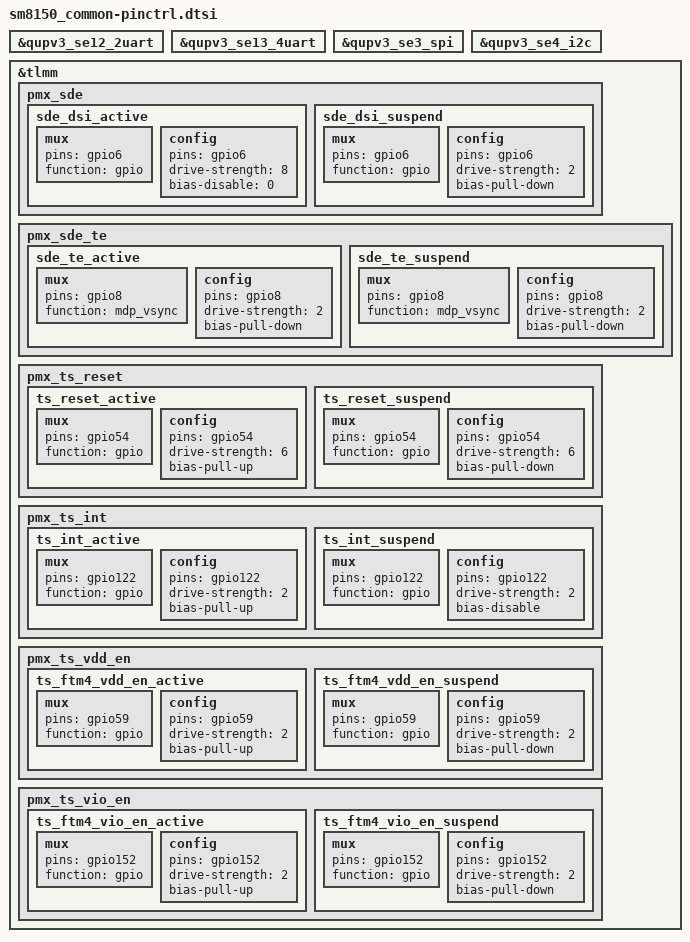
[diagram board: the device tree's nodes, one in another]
// SPDX-License-Identifier: GPL-2.0

&qupv3_se12_2uart {
	status = "ok";
};

&qupv3_se13_4uart {
	status = "ok";
};

&qupv3_se3_spi {
	status = "ok";
};

&qupv3_se4_i2c {
	status = "ok";
};

&tlmm {
	pmx_sde: pmx_sde {
		sde_dsi_active: sde_dsi_active {
			mux {
				pins = "gpio6";
				function = "gpio";
			};

			config {
				pins = "gpio6";
				drive-strength = <8>;   /* 8 mA */
				bias-disable = <0>;   /* no pull */
			};
		};

		sde_dsi_suspend: sde_dsi_suspend {
			mux {
				pins = "gpio6";
				function = "gpio";
			};

			config {
				pins = "gpio6";
				drive-strength = <2>;   /* 2 mA */
				bias-pull-down;         /* PULL DOWN */
			};
		};
	};

	pmx_sde_te {
		sde_te_active: sde_te_active {
			mux {
				pins = "gpio8";
				function = "mdp_vsync";
			};

			config {
				pins = "gpio8";
				drive-strength = <2>;   /* 2 mA */
				bias-pull-down;         /* PULL DOWN */
			};
		};

		sde_te_suspend: sde_te_suspend {
			mux {
				pins = "gpio8";
				function = "mdp_vsync";
			};

			config {
				pins = "gpio8";
				drive-strength = <2>;   /* 2 mA */
				bias-pull-down;         /* PULL DOWN */
			};
		};
	};

	pmx_ts_reset {
		ts_reset_active: ts_reset_active {
			mux {
				pins = "gpio54";
				function = "gpio";
			};
			config {
				pins = "gpio54";
				drive-strength = <6>;
				bias-pull-up;
			};
		};

		ts_reset_suspend: ts_reset_suspend {
			mux {
				pins = "gpio54";
				function = "gpio";
			};
			config {
				pins = "gpio54";
				drive-strength = <6>;
				bias-pull-down;
			};
		};
	};

	pmx_ts_int {
		ts_int_active: ts_int_active {
			mux {
				pins = "gpio122";
				function = "gpio";
			};
			config {
				pins = "gpio122";
				drive-strength = <2>;
				bias-pull-up;
			};
		};

		ts_int_suspend: ts_int_suspend {
			mux {
				pins = "gpio122";
				function = "gpio";
			};
			config {
				pins = "gpio122";
				drive-strength = <2>;
				bias-disable;
			};
		};
	};

	pmx_ts_vdd_en {
		ts_ftm4_vdd_en_active: ts_ftm4_vdd_en_active {
			mux {
				pins = "gpio59";
				function = "gpio";
			};
			config {
				pins = "gpio59";
				drive-strength = <2>;
				bias-pull-up;
			};
		};

		ts_ftm4_vdd_en_suspend: ts_ftm4_vdd_en_suspend {
			mux {
				pins = "gpio59";
				function = "gpio";
			};
			config {
				pins = "gpio59";
				drive-strength = <2>;
				bias-pull-down;
			};
		};
	};

	pmx_ts_vio_en {
		ts_ftm4_vio_en_active: ts_ftm4_vio_en_active {
			mux {
				pins = "gpio152";
				function = "gpio";
			};
			config {
				pins = "gpio152";
				drive-strength = <2>;
				bias-pull-up;
			};
		};

		ts_ftm4_vio_en_suspend: ts_ftm4_vio_en_suspend {
			mux {
				pins = "gpio152";
				function = "gpio";
			};
			config {
				pins = "gpio152";
				drive-strength = <2>;
				bias-pull-down;
			};
		};
	};
};
